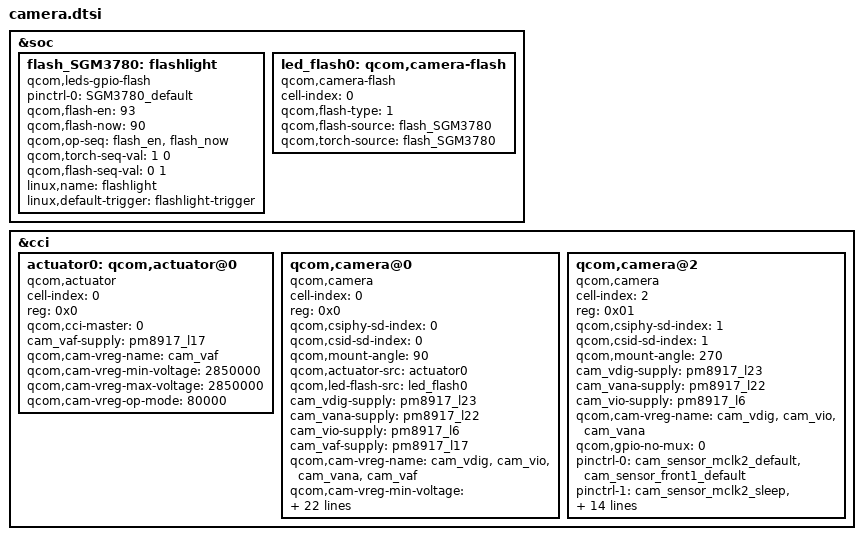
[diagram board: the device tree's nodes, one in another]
/* From stock msm8917-camera-sensor-qrd-s8850?.dtsi */
&soc {
	flash_SGM3780:flashlight {
		compatible = "qcom,leds-gpio-flash";
		status = "okay";
		pinctrl-names = "flash_default";
		pinctrl-0 = <&SGM3780_default>;
		qcom,flash-en = <93>;
		qcom,flash-now = <90>;
		qcom,op-seq = "flash_en", "flash_now";
		qcom,torch-seq-val = <1 0>;
		qcom,flash-seq-val = <0 1>;
		linux,name = "flashlight";
		linux,default-trigger = "flashlight-trigger";
	};
	led_flash0: qcom,camera-flash {
		cell-index = <0>;
		compatible = "qcom,camera-flash";
		qcom,flash-type = <1>; // WARNING: Overridden by msm8917-pmi8937-qrd-sku5_S8850?.dtsi, Original value is 3
		qcom,flash-source = <&flash_SGM3780>;
		qcom,torch-source = <&flash_SGM3780>;
	};
};
&cci {
	actuator0: qcom,actuator@0 {
		cell-index = <0>;
		reg = <0x0>;
		compatible = "qcom,actuator";
		qcom,cci-master = <0>;
		cam_vaf-supply = <&pm8917_l17>;
		qcom,cam-vreg-name = "cam_vaf";
		qcom,cam-vreg-min-voltage = <2850000>;
		qcom,cam-vreg-max-voltage = <2850000>;
		qcom,cam-vreg-op-mode = <80000>;
	};
	qcom,camera@0 {
		cell-index = <0>;
		compatible = "qcom,camera";
		reg = <0x0>;
		qcom,csiphy-sd-index = <0>;
		qcom,csid-sd-index = <0>;
		qcom,mount-angle = <90>;
		qcom,actuator-src = <&actuator0>;
		qcom,led-flash-src = <&led_flash0>;
		cam_vdig-supply = <&pm8917_l23>;
		cam_vana-supply = <&pm8917_l22>;
		cam_vio-supply = <&pm8917_l6>;
		cam_vaf-supply = <&pm8917_l17>;
		qcom,cam-vreg-name = "cam_vdig", "cam_vio", "cam_vana",
							"cam_vaf";
		qcom,cam-vreg-min-voltage = <1200000 1800000 2800000 2850000>;
		qcom,cam-vreg-max-voltage = <1200000 1800000 2800000 2850000>;
		qcom,cam-vreg-op-mode = <200000 80000 80000 100000>;
		pinctrl-names = "cam_default", "cam_suspend";
		pinctrl-0 = <&cam_sensor_mclk0_default
				&cam_sensor_rear_default>;
		pinctrl-1 = <&cam_sensor_mclk0_sleep
				&cam_sensor_rear_sleep>;
		gpios = <&tlmm 26 0>,
			<&tlmm 35 0>,
			<&tlmm 36 0>;
		qcom,gpio-reset = <1>;
		qcom,gpio-standby = <2>;
		qcom,gpio-req-tbl-num = <0 1 2>;
		qcom,gpio-req-tbl-flags = <1 0 0>;
		qcom,gpio-req-tbl-label = "CAMIF_MCLK0",
			"CAM_RESET0",
			"CAM_STANDBY0";
		qcom,sensor-position = <0>;
		qcom,sensor-mode = <0>;
		qcom,cci-master = <0>;
		clocks = <&clock_gcc clk_mclk0_clk_src>,
			<&clock_gcc clk_gcc_camss_mclk0_clk>;
		clock-names = "cam_src_clk", "cam_clk";
		qcom,clock-rates = <24000000 0>;
	};
	qcom,camera@2 {
		cell-index = <2>;
		compatible = "qcom,camera";
		reg = <0x01>;
		qcom,csiphy-sd-index = <1>;
		qcom,csid-sd-index = <1>;
		qcom,mount-angle = <270>;
		cam_vdig-supply = <&pm8917_l23>;
		cam_vana-supply = <&pm8917_l22>;
		cam_vio-supply = <&pm8917_l6>;
		qcom,cam-vreg-name = "cam_vdig", "cam_vio", "cam_vana";
		qcom,gpio-no-mux = <0>;
		pinctrl-names = "cam_default", "cam_suspend";
		pinctrl-0 = <&cam_sensor_mclk2_default
				&cam_sensor_front1_default>;
		pinctrl-1 = <&cam_sensor_mclk2_sleep
				&cam_sensor_front1_sleep>;
		gpios = <&tlmm 28 0>,
			<&tlmm 40 0>,
			<&tlmm 39 0>;
		qcom,gpio-reset = <1>;
		qcom,gpio-standby = <2>;
		qcom,gpio-req-tbl-num = <0 1 2>;
		qcom,gpio-req-tbl-flags = <1 0 0>;
		qcom,gpio-req-tbl-label = "CAMIF_MCLK2",
					  "CAM_RESET2",
					  "CAM_STANDBY2";
		qcom,sensor-position = <1>;
		qcom,sensor-mode = <0>;
		qcom,cci-master = <0>;
		clocks = <&clock_gcc clk_mclk2_clk_src>,
			<&clock_gcc clk_gcc_camss_mclk2_clk>;
		clock-names = "cam_src_clk", "cam_clk";
		qcom,clock-rates = <24000000 0>;
	};
};
